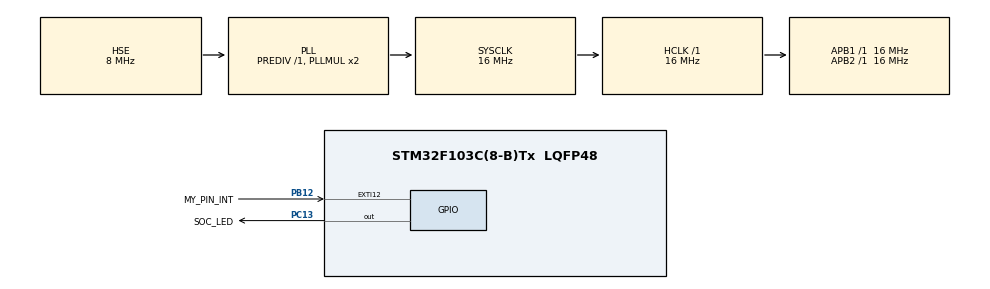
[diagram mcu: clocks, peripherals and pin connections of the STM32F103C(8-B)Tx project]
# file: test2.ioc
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Mcu.Family=STM32F1
NVIC.FLASH_IRQn=true\:5\:0\:false\:false\:true\:true\:true\:true
RCC.PLLSourceVirtual=RCC_PLLSOURCE_HSE
FREERTOS.Tasks01=defaultTask,24,128,StartDefaultTask,Default,NULL,Dynamic,NULL,NULL
PD1-OSC_OUT.Mode=HSE-External-Oscillator
PC13-TAMPER-RTC.Signal=GPIO_Output
PD0-OSC_IN.Signal=RCC_OSC_IN
RCC.SYSCLKSource=RCC_SYSCLKSOURCE_PLLCLK
ProjectManager.StackSize=0x400
VP_FREERTOS_VS_CMSIS_V2.Mode=CMSIS_V2
PD1-OSC_OUT.Signal=RCC_OSC_OUT
PA13.Signal=SYS_JTMS-SWDIO
ProjectManager.TargetToolchain=Makefile
RCC.HCLKFreq_Value=16000000
RCC.APB2TimFreq_Value=16000000
RCC.USBFreq_Value=16000000
RCC.AHBFreq_Value=16000000
PD0-OSC_IN.Mode=HSE-External-Oscillator
NVIC.EXTI15_10_IRQn=true\:5\:0\:false\:false\:true\:true\:true\:true
board=custom
PC13-TAMPER-RTC.GPIO_Label=SOC_LED
PB12.GPIO_Label=MY_PIN_INT
RCC.APB2Freq_Value=16000000
PA14.Mode=Serial_Wire
NVIC.TIM2_IRQn=true\:0\:0\:false\:false\:true\:false\:false\:true
FREERTOS.INCLUDE_xEventGroupSetBitFromISR=1
PC13-TAMPER-RTC.GPIO_Speed=GPIO_SPEED_FREQ_HIGH
PA13.Mode=Serial_Wire
Mcu.Name=STM32F103C(8-B)Tx
RCC.SYSCLKFreq_VALUE=16000000
Mcu.Package=LQFP48
PC13-TAMPER-RTC.GPIO_ModeDefaultOutputPP=GPIO_MODE_OUTPUT_PP
VP_SYS_VS_tim2.Mode=TIM2
FREERTOS.configUSE_NEWLIB_REENTRANT=1
FREERTOS.INCLUDE_xTaskAbortDelay=1
NVIC.TimeBase=TIM2_IRQn
PC13-TAMPER-RTC.GPIO_PuPd=GPIO_NOPULL
NVIC.TimeBaseIP=TIM2
PA14.Signal=SYS_JTCK-SWCLK
ProjectManager.HeapSize=0x200
FREERTOS.INCLUDE_xTaskGetHandle=1
PB12.GPIO_ModeDefaultEXTI=GPIO_MODE_IT_RISING_FALLING
NVIC.PriorityGroup=NVIC_PRIORITYGROUP_4
RCC.APB1TimFreq_Value=16000000
PB12.GPIO_PuPd=GPIO_PULLDOWN
RCC.APB1Freq_Value=16000000
PB12.Signal=GPXTI12

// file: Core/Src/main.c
/* USER CODE BEGIN Header */
/**
  ******************************************************************************
  * @file           : main.c
  * @brief          : Main program body
  ******************************************************************************
  * @attention
  *
  * <h2><center>&copy; Copyright (c) 2020 STMicroelectronics.
  * All rights reserved.</center></h2>
  *
  * This software component is licensed by ST under Ultimate Liberty license
  * SLA0044, the "License"; You may not use this file except in compliance with
  * the License. You may obtain a copy of the License at:
  *                             www.st.com/SLA0044
  *
  ******************************************************************************
  */
/* USER CODE END Header */

#include "main.h"
#include "cmsis_os.h"

/* USER CODE BEGIN Includes */
#include "FreeRTOSConfig.h"
#include "FreeRTOS.h"
#include "task.h"
#include "event_groups.h"
/* USER CODE END Includes */

/* USER CODE BEGIN PM */
EventGroupHandle_t xEvtLed;

/* USER CODE END PM */

/* Definitions for defaultTask */
osThreadId_t defaultTaskHandle;
const osThreadAttr_t defaultTask_attributes = {
  .name = "defaultTask",
  .priority = (osPriority_t) osPriorityNormal,
  .stack_size = 128 * 4
};
/* USER CODE BEGIN PV */
void SystemClock_Config(void);
static void MX_GPIO_Init(void);
void StartDefaultTask(void *argument);
static EventGroupHandle_t xEventLed;
#define EVENT_BITS_LED 0xFFFF

/* USER CODE END PV */

void SystemClock_Config(void);
static void MX_GPIO_Init(void);
void StartDefaultTask(void *argument);

int main(void)
{

  /* MCU Configuration--------------------------------------------------------*/

  /* Reset of all peripherals, Initializes the Flash interface and the Systick. */
  HAL_Init();

  /* Configure the system clock */
  SystemClock_Config();

  /* Initialize all configured peripherals */
  MX_GPIO_Init();
  /* USER CODE BEGIN 2 */
  xEventLed = xEventGroupCreate();

  /* USER CODE END 2 */

  /* Init scheduler */
  osKernelInitialize();

  /* Create the thread(s) */
  /* creation of defaultTask */
  defaultTaskHandle = osThreadNew(StartDefaultTask, NULL, &defaultTask_attributes);

  /* Start scheduler */
  osKernelStart();

  /* We should never get here as control is now taken by the scheduler */
  /* Infinite loop */
  while (1)
  {

  }
}

void SystemClock_Config(void)
{
  RCC_OscInitTypeDef RCC_OscInitStruct = {0};
  RCC_ClkInitTypeDef RCC_ClkInitStruct = {0};

  /** Initializes the CPU, AHB and APB busses clocks
  */
  RCC_OscInitStruct.OscillatorType = RCC_OSCILLATORTYPE_HSE;
  RCC_OscInitStruct.HSEState = RCC_HSE_ON;
  RCC_OscInitStruct.HSEPredivValue = RCC_HSE_PREDIV_DIV1;
  RCC_OscInitStruct.HSIState = RCC_HSI_ON;
  RCC_OscInitStruct.PLL.PLLState = RCC_PLL_ON;
  RCC_OscInitStruct.PLL.PLLSource = RCC_PLLSOURCE_HSE;
  RCC_OscInitStruct.PLL.PLLMUL = RCC_PLL_MUL2;
  if (HAL_RCC_OscConfig(&RCC_OscInitStruct) != HAL_OK)
  {
    Error_Handler();
  }
  /** Initializes the CPU, AHB and APB busses clocks
  */
  RCC_ClkInitStruct.ClockType = RCC_CLOCKTYPE_HCLK|RCC_CLOCKTYPE_SYSCLK
                              |RCC_CLOCKTYPE_PCLK1|RCC_CLOCKTYPE_PCLK2;
  RCC_ClkInitStruct.SYSCLKSource = RCC_SYSCLKSOURCE_PLLCLK;
  RCC_ClkInitStruct.AHBCLKDivider = RCC_SYSCLK_DIV1;
  RCC_ClkInitStruct.APB1CLKDivider = RCC_HCLK_DIV1;
  RCC_ClkInitStruct.APB2CLKDivider = RCC_HCLK_DIV1;

  if (HAL_RCC_ClockConfig(&RCC_ClkInitStruct, FLASH_LATENCY_0) != HAL_OK)
  {
    Error_Handler();
  }
}

static void MX_GPIO_Init(void)
{
  GPIO_InitTypeDef GPIO_InitStruct = {0};

  /* GPIO Ports Clock Enable */
  __HAL_RCC_GPIOC_CLK_ENABLE();
  __HAL_RCC_GPIOD_CLK_ENABLE();
  __HAL_RCC_GPIOB_CLK_ENABLE();
  __HAL_RCC_GPIOA_CLK_ENABLE();

  /*Configure GPIO pin Output Level */
  HAL_GPIO_WritePin(SOC_LED_GPIO_Port, SOC_LED_Pin, GPIO_PIN_RESET);

  /*Configure GPIO pin : SOC_LED_Pin */
  GPIO_InitStruct.Pin = SOC_LED_Pin;
  GPIO_InitStruct.Mode = GPIO_MODE_OUTPUT_PP;
  GPIO_InitStruct.Pull = GPIO_NOPULL;
  GPIO_InitStruct.Speed = GPIO_SPEED_FREQ_HIGH;
  HAL_GPIO_Init(SOC_LED_GPIO_Port, &GPIO_InitStruct);

  /*Configure GPIO pin : MY_PIN_INT_Pin */
  GPIO_InitStruct.Pin = MY_PIN_INT_Pin;
  GPIO_InitStruct.Mode = GPIO_MODE_IT_RISING_FALLING;
  GPIO_InitStruct.Pull = GPIO_PULLDOWN;
  HAL_GPIO_Init(MY_PIN_INT_GPIO_Port, &GPIO_InitStruct);

  /* EXTI interrupt init*/
  HAL_NVIC_SetPriority(EXTI15_10_IRQn, 5, 0);
  HAL_NVIC_EnableIRQ(EXTI15_10_IRQn);

}

/* USER CODE BEGIN 4 */
void HAL_GPIO_EXTI_Callback(uint16_t pinNum){
  if(pinNum == MY_PIN_INT_Pin){
    xEventGroupSetBitsFromISR(xEventLed, 1, NULL);
  }
}
/* USER CODE END 4 */

void StartDefaultTask(void *argument)
{
  /* USER CODE BEGIN 5 */
  /* Infinite loop */

  // //LED OFF when pin high
  HAL_GPIO_WritePin(GPIOC, GPIO_PIN_13, 1);
  /* Infinite loop */
  #define BLINK_PERIOD 500
  #define BLINK_TIMES 10
  int blinkCnt = 0;
  for(int cnt = 0; ;cnt++)
  {
    EventBits_t bits = xEventGroupWaitBits(xEventLed, EVENT_BITS_LED, pdTRUE, pdFALSE, 500/portTICK_PERIOD_MS);
    if((bits &1 )|| blinkCnt > 0){
      if(blinkCnt == 0){
        blinkCnt = BLINK_TIMES;
      }
      HAL_GPIO_WritePin(GPIOC, GPIO_PIN_13, cnt%2);
      blinkCnt--;
    }
  }
  /* USER CODE END 5 */
}

 /**
  * @brief  Period elapsed callback in non blocking mode
  * @note   This function is called  when TIM2 interrupt took place, inside
  * HAL_TIM_IRQHandler(). It makes a direct call to HAL_IncTick() to increment
  * a global variable "uwTick" used as application time base.
  * @param  htim : TIM handle
  * @retval None
  */
void HAL_TIM_PeriodElapsedCallback(TIM_HandleTypeDef *htim)
{
  if (htim->Instance == TIM2) {
    HAL_IncTick();
  }
}

void Error_Handler(void)
{
}

/************************ (C) COPYRIGHT STMicroelectronics *****END OF FILE****/
